# NUC1311AE_v1 register map
File version: 1.0
Registers are 32-bit, read-write, reset 0x0 unless marked. A register's access mark holds for its fields unless they carry their own. Offsets are from the block's base; [hi:lo] are bit positions; {n}, {i} and the like mark numbered series.

## FMC — FMC Register Map
Base 0x5000C000
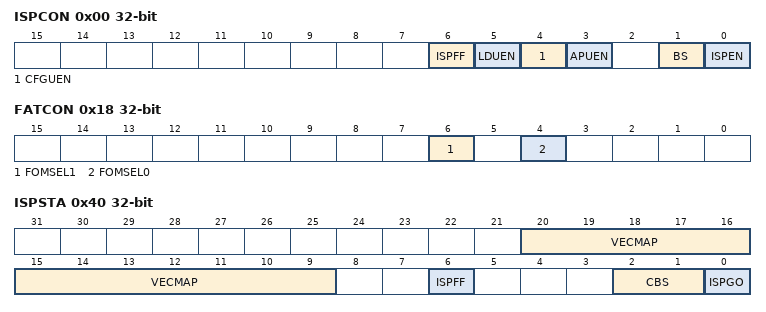
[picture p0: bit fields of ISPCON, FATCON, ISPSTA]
0x00 ISPCON — ISP Control Register
  [6] ISPFF — ISP Fail Flag (Write Protect). This bit is set by hardware when a triggered ISP meets any of the following conditions: (1) APROM writes to itself if APUEN is set to 0. (2) LDROM writes to itself if LDUEN is set to 0. (3) CONFIG is erased/programmed if CFGUEN is set to 0. (4) Destination address is illegal, such as over an available range. Write 1 to clear to this bit to 0.
  [5] LDUEN — LDROM Update Enable Control (Write Protect)
    0=LDROM cannot be updated; 1=LDROM can be updated when chip runs in APROM
  [4] CFGUEN — Enable Config Update By ISP (Write Protect)
    0=ISP update config-bit Disabled; 1=ISP update config-bit Enabled
  [3] APUEN — APROM Update Enable Control (Write Protect)
    0=APROM cannot be updated when chip runs in APROM; 1=APROM can be updated when chip runs in APROM
  [1] BS — Boot Select (Write Protect ). Set/clear this bit to select next booting from LDROM/APROM, respectively. This bit also functions as chip booting status flag, which can be used to check where chip booted from. This bit is initiated with the inversed value of CBS in CONFIG0 after any reset is happened except CPU reset (RSTS_CPU is 1) or system reset (RSTS_SYS) is happened.
    0=Boot from APROM; 1=Boot from LDROM
  [0] ISPEN — ISP Enable Control (Write Protect ). ISP function enable bit. Set this bit to enable ISP function.
    0=ISP function Disabled; 1=ISP function Enabled
0x04 ISPADR — ISP Address Register
  [31:0] ISPADR — ISP Address. The NuMicro( NUC1311 series has a maximum of 17Kx32 (68 KB) embedded Flash, which supports word program only. ISPADR[1:0] must be kept 00b for ISP operation.
0x08 ISPDAT — ISP Data Register
  [31:0] ISPDAT — ISP Data. Write data to this register before ISP program operation. Read data from this register after ISP read operation.
0x0C ISPCMD — ISP Command Register
  [5:0] ISPCMD — ISP Command. ISP command table is shown below:
    0=Read; 4=Read Unique ID; 11=Read Company ID (0xDA); 33=Program; 34=Page Erase; 46=Set Vector Page Re-Map
0x10 ISPTRG — ISP Trigger Control Register
  [0] ISPGO — ISP Start Trigger (Write Protect). Write 1 to start ISP operation and this bit will be cleared to 0 by hardware automatically when ISP operation is finished. This bit is the protected bit, It means programming this bit needs to write "59h", "16h", "88h" to address 0x5000_0100 to disable register protection. Refer to the register REGWRPROT at address GCR_BA+0x100.
    0=ISP operation finished; 1=ISP is in progress
0x14 DFBADR ro (reset mask 0xFFF00000) — Data Flash Base Address
  [31:0] DFBADR — Data Flash Base Address. This register indicates Data Flash start address. It is read only. When DFVSEN is set to 0, the data flash is shared with APROM. The data flash size is defined by user configuration and the content of this register is loaded from Config1. When DFVSEN is set to 1, the data flash size is fixed as 4K and the start address can be read from this register is fixed at 0x0001_F000.
0x18 FATCON — Flash Access Time Control Register
  [6] FOMSEL1 — Chip Frequency Optimization Mode Select1 (Write-protection Bit)
  [4] FOMSEL0 — Chip Frequency Optimization Mode Select 0 (Write-Protection Bit). When CPU frequency is lower than 25 MHz, user can modify flash access delay cycle by FOMSEL1 and FOMSEL0 to improve system performance.
0x40 ISPSTA — ISP Status Register
  [20:9] VECMAP ro — Vector Page Mapping Address (Read Only). The current flash address space 0x0000_0000~0x0000_01FF is mapping to address {VECMAP[11:0], 9'h000} ~ {VECMAP[11:0], 9'h1FF}.
  [6] ISPFF — ISP Fail Flag (Write-Protection Bit). This bit is set by hardware when a triggered ISP meets any of the following conditions: (1) APROM writes to itself (2) LDROM writes to itself (3) CONFIG is erased/programmed if CFGUEN is set to 0 (4) Destination address is illegal, such as over an available range. Write 1 to clear this bit. Note: The function of this bit is the same as ISPCON bit6.
  [2:1] CBS ro — Chip Boot Selection (Read Only). This is a mirror of CBS in CONFIG0.
  [0] ISPGO ro — ISP Start Trigger (Read Only). Write 1 to start ISP operation and this bit will be cleared to 0 by hardware automatically when ISP operation is finished. Note: This bit is the same as ISPTRG bit0.
    0=ISP operation finished; 1=ISP operation progressed
